# PRM_WKUP register map
Vendor: Texas Instruments
Peripheral module from a debugger description file (folder am437x).
Registers are 32-bit, access per field, no defined reset value unless marked. A register's access mark holds for its fields unless they carry their own. Offsets are as the file gives them; lines under a group give offsets from that group; [hi:lo] are bit positions; {n}, {i} and the like mark numbered series; 'fields as' and 'values as' point back to an identical list; <NAME> marks a mode.

## PRM_WKUP
0x10 PRCM_RM_WKUP_RSTCTRL — This register controls the release of the ALWAYS ON Domain resets.
  [3] WKUP_PROC_LRST rw — Assert Reset to WKUP_PROC
    1=en_2_0x1 (Reset is asserted for the Wakeup Processor by the A9); 0=en_1_0x0 (Reset is cleared for the Wakeup Processor)
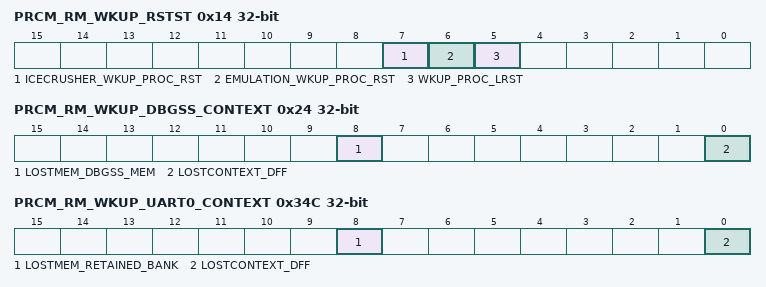
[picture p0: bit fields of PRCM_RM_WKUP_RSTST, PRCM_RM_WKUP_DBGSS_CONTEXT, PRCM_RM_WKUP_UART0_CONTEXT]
0x14 PRCM_RM_WKUP_RSTST — This register logs the different reset sources of the ALWON domain. Each bit is set upon release of the domain reset signal. Must be cleared by software. [warm reset insensitive]
  [all] fields
    1=en_2_0x1 (Wakeup Processor has been reset); 0=en_1_0x0 (No reset)
  [7] ICECRUSHER_WKUP_PROC_RST rw — Wakeup Processor has been reset due to Wakeup Processor ICECRUSHER1 reset event
  [6] EMULATION_WKUP_PROC_RST rw — Wakeup Processor has been reset due to emulation reset source e.g. [[br]]assert reset command initiated by the icepick module
  [5] WKUP_PROC_LRST rw — Wakeup Processor has been reset
0x24 PRCM_RM_WKUP_DBGSS_CONTEXT — This register contains dedicated DEBUGSS module context statuses. [warm reset insensitive]
  [8] LOSTMEM_DBGSS_MEM rw — Specify if memory-based context in DEBUGSS_MEM memory bank has been lost due to a previous power transition or other reset source.
    1=en_2_0x1 (Context has been lost); 0=en_1_0x0 (Context has been maintained)
  [0] LOSTCONTEXT_DFF rw — Specify if DFF-based context has been lost due to a previous power transition or other reset source. [[br]](set upon assertion of EMU_RST signal)
    values as LOSTMEM_DBGSS_MEM
0x124 PRCM_RM_WKUP_ADC0_CONTEXT — This register contains dedicated ADC0 module context statuses.
  [0] LOSTCONTEXT_DFF rw — Specify if DFF-based context has been lost due to a previous power transition or other reset source. [[br]](set upon assertion of WKUP_DOM_RST signal)
    values as PRCM_RM_WKUP_DBGSS_CONTEXT.LOSTMEM_DBGSS_MEM
0x224 PRCM_RM_WKUP_L4WKUP_CONTEXT — This register contains dedicated L4WKUP module context statuses. [warm reset insensitive]
  fields as PRCM_RM_WKUP_ADC0_CONTEXT
0x22C PRCM_RM_WKUP_PROC_CONTEXT — This register contains dedicated WKUP_M3 module context statuses. [warm reset insensitive]
  [0] LOSTCONTEXT_DFF rw — Specify if DFF-based context has been lost due to a previous power transition or other reset source. [[br]](set upon assertion of WKUP_PROC_LRST signal)
    values as PRCM_RM_WKUP_DBGSS_CONTEXT.LOSTMEM_DBGSS_MEM
0x234 PRCM_RM_WKUP_SYNCTIMER_CONTEXT — This register contains dedicated SYNCTIMER module context statuses. [warm reset insensitive]
  [0] LOSTCONTEXT_DFF rw — Specify if DFF-based context has been lost due to a previous power transition or other reset source. [[br]](set upon assertion of WKUP_SYS_PWRON_RST signal)
    values as PRCM_RM_WKUP_DBGSS_CONTEXT.LOSTMEM_DBGSS_MEM
0x324 PRCM_RM_WKUP_TIMER0_CONTEXT — This register contains dedicated TIMER0 module context statuses. [warm reset insensitive]
  fields as PRCM_RM_WKUP_ADC0_CONTEXT
0x32C PRCM_RM_WKUP_TIMER1_CONTEXT — This register contains dedicated TIMER1 module context statuses. [warm reset insensitive]
  fields as PRCM_RM_WKUP_ADC0_CONTEXT
0x33C PRCM_RM_WKUP_WDT1_CONTEXT — This register contains dedicated WDT1 module context statuses. [warm reset insensitive]
  [0] LOSTCONTEXT_DFF rw — Specify if DFF-based context has been lost due to a previous power transition or other reset source. [[br]](set upon assertion of WKUP_RST signal)
    values as PRCM_RM_WKUP_DBGSS_CONTEXT.LOSTMEM_DBGSS_MEM
0x344 PRCM_RM_WKUP_I2C0_CONTEXT — This register contains dedicated I2C0 module context statuses. [warm reset insensitive]
  fields as PRCM_RM_WKUP_ADC0_CONTEXT
0x34C PRCM_RM_WKUP_UART0_CONTEXT — This register contains dedicated UART0 module context statuses. [warm reset insensitive]
  [8] LOSTMEM_RETAINED_BANK rw — Specify if memory-based context in RETAINED_BANK memory bank has been lost due to a previous power transition or other reset source.
    values as PRCM_RM_WKUP_DBGSS_CONTEXT.LOSTMEM_DBGSS_MEM
  [0] LOSTCONTEXT_DFF rw — Specify if DFF-based context has been lost due to a previous power transition or other reset source. [[br]](set upon assertion of WKUP_DOM_RST signal)
    values as PRCM_RM_WKUP_DBGSS_CONTEXT.LOSTMEM_DBGSS_MEM
0x354 PRCM_RM_WKUP_SMARTREFLEX0_CONTEXT — This register contains dedicated SMARTREFLEX0 module context statuses. [warm reset insensitive]
  fields as PRCM_RM_WKUP_ADC0_CONTEXT
0x35C PRCM_RM_WKUP_SMARTREFLEX1_CONTEXT — This register contains dedicated SMARTREFLEX1 module context statuses. [warm reset insensitive]
  fields as PRCM_RM_WKUP_ADC0_CONTEXT
0x36C PRCM_RM_WKUP_GPIO0_CONTEXT — This register contains dedicated GPIO0 module context statuses. [warm reset insensitive]
  fields as PRCM_RM_WKUP_ADC0_CONTEXT
